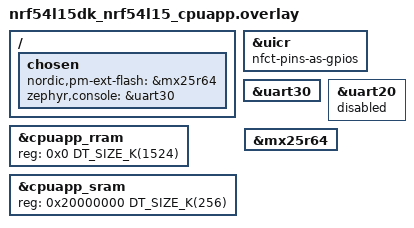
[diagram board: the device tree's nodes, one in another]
/* overlay file for app core */

/ {
	chosen {
		nordic,pm-ext-flash = &mx25r64;
		zephyr,console = &uart30;
	};		
};

&uicr {
	nfct-pins-as-gpios;
};

&uart30 {
	status = "okay";
	/delete-property/ rts-pin;
	/delete-property/ cts-pin;
	/delete-property/ hw-flow-control;
};

&uart20 {
	status = "disabled";
};

// restore full RRAM and SRAM space - by default some parts are dedicated to FLRP
&cpuapp_rram {
	reg = <0x0 DT_SIZE_K(1524)>;
};

&cpuapp_sram {
	reg = <0x20000000 DT_SIZE_K(256)>;
	ranges = <0x0 0x20000000  0x40000>;
};

&mx25r64 {
	status = "okay";
};
